# FM33FG0XXA register map
File version: 1.0
CPU: SC000 r1p0, little endian, MPU, no FPU, 3 interrupt priority bits
Registers are 32-bit, read-only, reset 0x0 unless marked. A register's access mark holds for its fields unless they carry their own. Offsets are from the block's base; [hi:lo] are bit positions; {n}, {i} and the like mark numbered series.

## RTC — RTC module information
Base 0x40011000
0x00 WER rw — RTC Write Enable Register
  [0] WE — WE field description
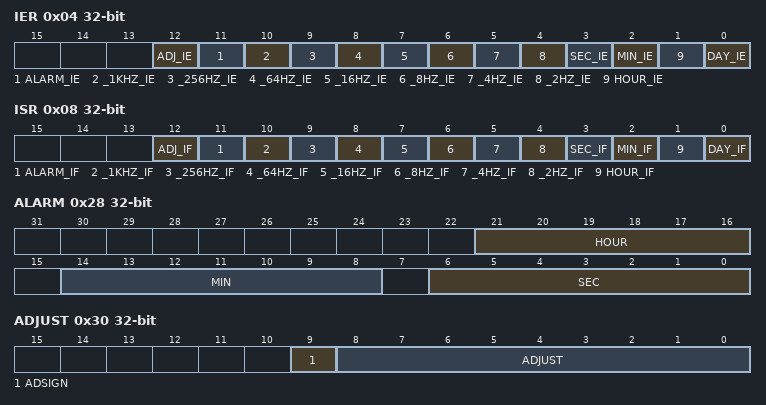
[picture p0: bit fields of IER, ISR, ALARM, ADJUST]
0x04 IER rw — RTC Interrupt Enable Register
  [12] ADJ_IE — ADJ_IE field description
  [11] ALARM_IE — ALARM_IE field description
  [10] _1KHZ_IE — _1KHZ_IE field description
  [9] _256HZ_IE — _256HZ_IE field description
  [8] _64HZ_IE — _64HZ_IE field description
  [7] _16HZ_IE — _16HZ_IE field description
  [6] _8HZ_IE — _8HZ_IE field description
  [5] _4HZ_IE — _4HZ_IE field description
  [4] _2HZ_IE — _2HZ_IE field description
  [3] SEC_IE — SEC_IE field description
  [2] MIN_IE — MIN_IE field description
  [1] HOUR_IE — HOUR_IE field description
  [0] DAY_IE — DAY_IE field description
0x08 ISR rw — RTC Interrupt Status Register
  [12] ADJ_IF — ADJ_IF field description
  [11] ALARM_IF — ALARM_IF field description
  [10] _1KHZ_IF — _1KHZ_IF field description
  [9] _256HZ_IF — _256HZ_IF field description
  [8] _64HZ_IF — _64HZ_IF field description
  [7] _16HZ_IF — _16HZ_IF field description
  [6] _8HZ_IF — _8HZ_IF field description
  [5] _4HZ_IF — _4HZ_IF field description
  [4] _2HZ_IF — _2HZ_IF field description
  [3] SEC_IF — SEC_IF field description
  [2] MIN_IF — MIN_IF field description
  [1] HOUR_IF — HOUR_IF field description
  [0] DAY_IF — DAY_IF field description
0x0C BCDSEC rw — BCD format time second registers
  [6:0] SEC — SEC field description
0x10 BCDMIN rw — BCD format time minute registers
  [6:0] MIN — MIN field description
0x14 BCDHOUR rw — BCD format time hour registers
  [5:0] HOUR — HOUR field description
0x18 BCDDAY rw — BCD format time day registers
  [5:0] DAY — DAY field description
0x1C BCDWEEK rw — BCD format time week registers
  [2:0] WEEK — WEEK field description
0x20 BCDMONTH rw — BCD format time month registers
  [4:0] MONTH — MONTH field description
0x24 BCDYEAR rw — BCD format time year registers
  [7:0] YEAR — YEAR field description
0x28 ALARM rw — RTC Alarm Register
  [21:16] HOUR — HOUR field description
  [14:8] MIN — MIN field description
  [6:0] SEC — SEC field description
0x2C TMSEL rw — RTC Time Mark Select
  [3:0] TMSEL — TMSEL field description
0x30 ADJUST rw — RTC time Adjust Register
  [9] ADSIGN — ADSIGN field description
  [8:0] ADJUST — ADJUST field description
0x3C SBSCNT rw — RTC Sub-Second Counter
  [7:0] MSCNT — MSCNT field description
0x40 CR rw — RTC Control Register
  [0] EN — EN field description

## DAC — DAC module information
Base 0x40019000
0x00 CR1 rw — DAC Control Register
  [0] EN — EN field description
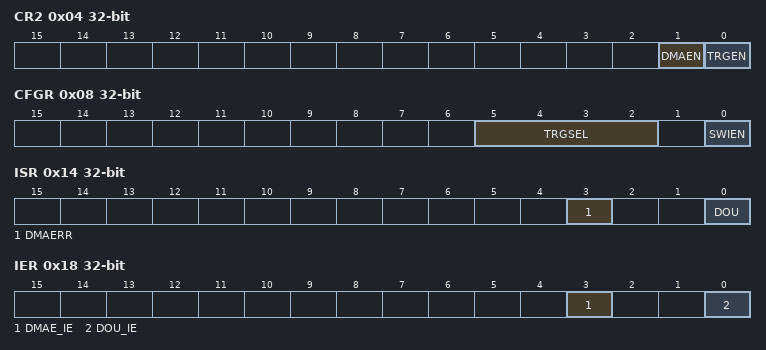
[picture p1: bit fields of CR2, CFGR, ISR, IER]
0x04 CR2 rw — DAC Control Register
  [1] DMAEN — DMAEN field description
  [0] TRGEN — TRGEN field description
0x08 CFGR rw — DAC Config Register
  [5:2] TRGSEL — TRGSEL field description
  [0] SWIEN — SWIEN field description
0x0C SWTRGR wo — DAC Software Trigger Register
  [0] SWTRIG — SWTRIG field description
0x10 DHR rw — DAC Data Holding Register
  [9:0] DHR — DHR field description
0x14 ISR rw — DAC Interrupt Status Register
  [3] DMAERR — DMAERR field description
  [0] DOU — DOU field description
0x18 IER rw — DAC Interrupt Enable Register
  [3] DMAE_IE — DMAE_IE field description
  [0] DOU_IE — DOU_IE field description

## PGL — PGL module information
Base 0x40016C00
0x00 CR rw
  [3:0] LUTEN — LUTEN field description
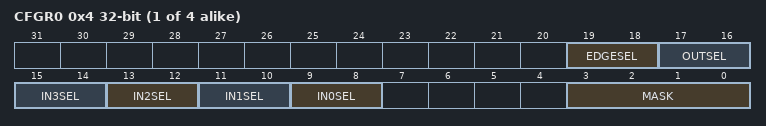
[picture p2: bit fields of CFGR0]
{0x4+4i} CFGR{i} rw (i=0..3)
  [19:18] EDGESEL — EDGESEL field description
  [17:16] OUTSEL — OUTSEL field description
  [2n+9:2n+8] IN{n}SEL (n=0..3) — IN{n}SEL field description
  [3:0] MASK — MASK field description
0x14 IER rw
  [3:0] LUTIE — LUTIE field description
0x18 ISR rw
  [3:0] LUTIF — LUTIF field description
{0x1C+4i} LUT{i} rw (i=0..3)
  [15:0] TRUTH — TRUTH field description

## GPIOA — GPIOA module information
Base 0x40000C00
Same registers: GPIOB 0x40000C40, GPIOC 0x40000C80, GPIOD 0x40000CC0, GPIOE 0x40000D00, GPIOF 0x40000D40, GPIOG 0x40000D80, GPIOH 0x40000DC0, GPIOI 0x40000E00
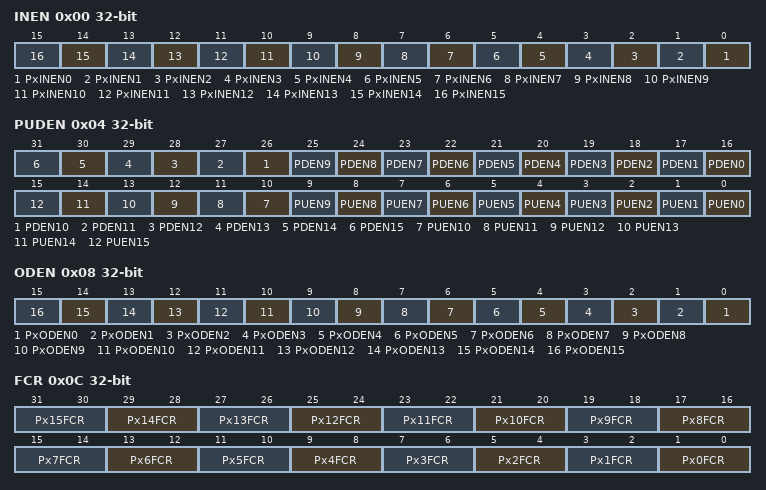
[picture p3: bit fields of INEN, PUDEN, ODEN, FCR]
0x00 INEN rw — GPIOA Input Enable Register
  [n] PxINEN{n} (n=0..15) — PxINEN{n} field description
0x04 PUDEN rw — GPIOA Pull-Up Pull-Down Enable Register
  [n+16] PDEN{n} (n=0..15) — PDEN{n} field description
  [n] PUEN{n} (n=0..15) — PUEN{n} field description
0x08 ODEN rw — GPIOA Open-Drain Enable Register
  [n] PxODEN{n} (n=0..15) — PxODEN{n} field description
0x0C FCR rw — GPIOA Function Control Register
  [2n+1:2n] Px{n}FCR (n=0..15) — Px{n}FCR field description
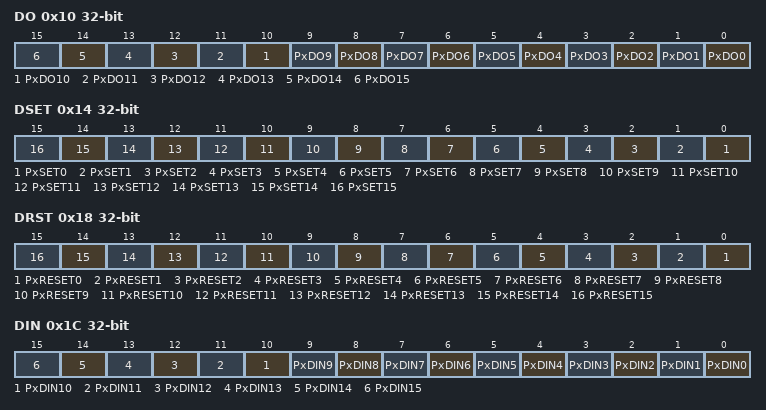
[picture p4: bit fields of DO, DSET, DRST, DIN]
0x10 DO rw — GPIOA Data Output Register
  [n] PxDO{n} (n=0..15) — PxDO{n} field description
0x14 DSET wo — GPIOA Data Set Register
  [n] PxSET{n} (n=0..15) — PxSET{n} field description
0x18 DRST wo — GPIOA Data Reset Register
  [n] PxRESET{n} (n=0..15) — PxRESET{n} field description
0x1C DIN — GPIOA Data Input Register
  [n] PxDIN{n} (n=0..15) — PxDIN{n} field description
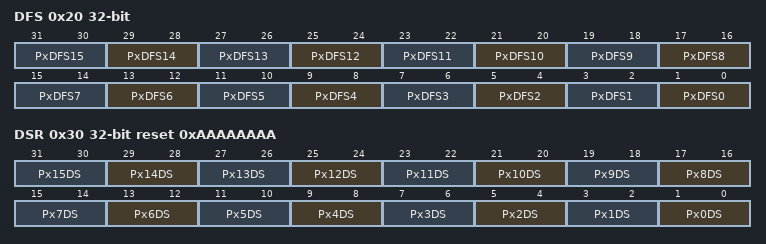
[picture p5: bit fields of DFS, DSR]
0x20 DFS rw — GPIOA Digital Function Select
  [2n+1:2n] PxDFS{n} (n=0..15) — PxDFS{n} field description
0x30 DSR rw reset 0xAAAAAAAA — GPIOA Driver Strength Register
  [2n+1:2n] Px{n}DS (n=0..15) — Px{n}DS field description

## SFU — SFU module information
Base 0x40001C00
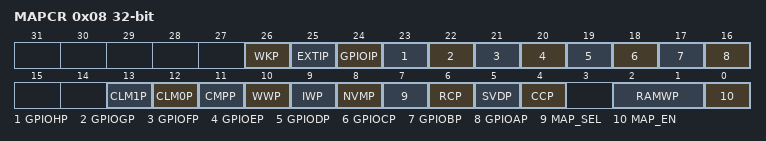
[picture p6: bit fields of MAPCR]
0x08 MAPCR rw — Memory Access Protection Control Register
  [26] WKP — WKP field description
  [25] EXTIP — EXTIP field description
  [24] GPIOIP — GPIOIP field description
  [23] GPIOHP — GPIOHP field description
  [22] GPIOGP — GPIOGP field description
  [21] GPIOFP — GPIOFP field description
  [20] GPIOEP — GPIOEP field description
  [19] GPIODP — GPIODP field description
  [18] GPIOCP — GPIOCP field description
  [17] GPIOBP — GPIOBP field description
  [16] GPIOAP — GPIOAP field description
  [13] CLM1P — CLM1P field description
  [12] CLM0P — CLM0P field description
  [11] CMPP — CMPP field description
  [10] WWP — WWP field description
  [9] IWP — IWP field description
  [8] NVMP — NVMP field description
  [7] MAP_SEL — MAP_SEL field description
  [6] RCP — RCP field description
  [5] SVDP — SVDP field description
  [4] CCP — CCP field description
  [2:1] RAMWP — RAMWP field description
  [0] MAP_EN — MAP_EN field description
0x0C MAPSR rw — Memory Access Protection Control Register
  [0] MAP_IF — MAP_IF field description

## DBG — DBG module information
Base 0x40000000
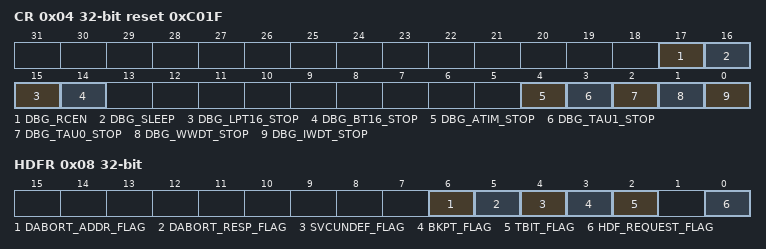
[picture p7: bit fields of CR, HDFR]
0x04 CR rw reset 0xC01F — MCU Debug Configuration Register
  [17] DBG_RCEN — DBG_RCEN field description
  [16] DBG_SLEEP — DBG_SLEEP field description
  [15] DBG_LPT16_STOP — DBG_LPT16_STOP field description
  [14] DBG_BT16_STOP — DBG_BT16_STOP field description
  [4] DBG_ATIM_STOP — DBG_ATIM_STOP field description
  [3] DBG_TAU1_STOP — DBG_TAU1_STOP field description
  [2] DBG_TAU0_STOP — DBG_TAU0_STOP field description
  [1] DBG_WWDT_STOP — DBG_WWDT_STOP field description
  [0] DBG_IWDT_STOP — DBG_IWDT_STOP field description
0x08 HDFR rw — Hradfault Query Register
  [6] DABORT_ADDR_FLAG — DABORT_ADDR_FLAG field description
  [5] DABORT_RESP_FLAG — DABORT_RESP_FLAG field description
  [4] SVCUNDEF_FLAG — SVCUNDEF_FLAG field description
  [3] BKPT_FLAG — BKPT_FLAG field description
  [2] TBIT_FLAG — TBIT_FLAG field description
  [0] HDF_REQUEST_FLAG — HDF_REQUEST_FLAG field description
